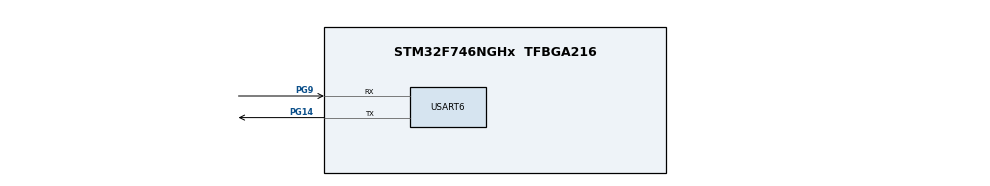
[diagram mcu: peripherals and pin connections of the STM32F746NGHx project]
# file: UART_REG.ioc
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Mcu.Family=STM32F7
Mcu.Name=STM32F746NGHx
Mcu.Package=TFBGA216
NVIC.PriorityGroup=NVIC_PRIORITYGROUP_4
NVIC.USART6_IRQn=true\:0\:0\:false\:false\:true\:true\:true\:true
PG14.Mode=Asynchronous
PG14.Signal=USART6_TX
PG9.Mode=Asynchronous
PG9.Signal=USART6_RX
ProjectManager.HeapSize=0x200
ProjectManager.StackSize=0x400
ProjectManager.TargetToolchain=STM32CubeIDE
RCC.HSE_VALUE=25000000
RCC.HSI_VALUE=16000000
RCC.LSE_VALUE=32768
RCC.USBFreq_Value=96000000
RCC.VCOOutputFreq_Value=192000000
USART6.VirtualMode-Asynchronous=VM_ASYNC
board=custom

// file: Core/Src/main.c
/* USER CODE BEGIN Header */
/**
  ******************************************************************************
  * @file           : main.c
  * @brief          : Main program body
  ******************************************************************************
  * @attention
  *
  * Copyright (c) 2023 STMicroelectronics.
  * All rights reserved.
  *
  * This software is licensed under terms that can be found in the LICENSE file
  * in the root directory of this software component.
  * If no LICENSE file comes with this software, it is provided AS-IS.
  *
  ******************************************************************************
  */
/* USER CODE END Header */
#include "main.h"

UART_HandleTypeDef huart6;

void SystemClock_Config(void);
static void MX_GPIO_Init(void);
static void MX_USART6_UART_Init(void);

/* USER CODE BEGIN 0 */

void uart_Send(uint8_t Txdata)
{
	/*********** STEPS FOLLOWED *************

		1. Write the data to send in the USART_DR register (this clears the TXE bit). Repeat this
			 for each data to be transmitted in case of single buffer.
		2. After writing the last data into the USART_DR register, wait until TC=1. This indicates
			 that the transmission of the last frame is complete. This is required for instance when
			 the USART is disabled or enters the Halt mode to avoid corrupting the last transmission.
    */
	 USART6->TDR = Txdata;
	 while(!(USART6->ISR & (1 << 6)));

}

void uart_Send_IT(void)
{

}

uint8_t uart_Receive(void)
{
	                      /*********** STEPS FOLLOWED *************/

	//1. Wait for the RXNE bit to set. It indicates that the data has been received and can be read.
    //2. Read the data from USART_DR  Register. This also clears the RXNE bit.

	while(!(USART6->ISR & (1 << 5)));
	uint8_t temp = USART6->RDR;

	return temp;
}

uint8_t uart_Receive_IT(void)
{

}

/* USER CODE END 0 */

int main(void)
{

  /* MCU Configuration--------------------------------------------------------*/

  /* Reset of all peripherals, Initializes the Flash interface and the Systick. */
  HAL_Init();

  /* Configure the system clock */
  SystemClock_Config();

  /* Initialize all configured peripherals */
  MX_GPIO_Init();
  MX_USART6_UART_Init();

  /* Infinite loop */
  while (1)
  {

  }
}

void SystemClock_Config(void)
{
  RCC_OscInitTypeDef RCC_OscInitStruct = {0};
  RCC_ClkInitTypeDef RCC_ClkInitStruct = {0};

  /** Configure the main internal regulator output voltage
  */
  __HAL_RCC_PWR_CLK_ENABLE();
  __HAL_PWR_VOLTAGESCALING_CONFIG(PWR_REGULATOR_VOLTAGE_SCALE3);

  /** Initializes the RCC Oscillators according to the specified parameters
  * in the RCC_OscInitTypeDef structure.
  */
  RCC_OscInitStruct.OscillatorType = RCC_OSCILLATORTYPE_HSI;
  RCC_OscInitStruct.HSIState = RCC_HSI_ON;
  RCC_OscInitStruct.HSICalibrationValue = RCC_HSICALIBRATION_DEFAULT;
  RCC_OscInitStruct.PLL.PLLState = RCC_PLL_NONE;
  if (HAL_RCC_OscConfig(&RCC_OscInitStruct) != HAL_OK)
  {
    Error_Handler();
  }

  /** Initializes the CPU, AHB and APB buses clocks
  */
  RCC_ClkInitStruct.ClockType = RCC_CLOCKTYPE_HCLK|RCC_CLOCKTYPE_SYSCLK
                              |RCC_CLOCKTYPE_PCLK1|RCC_CLOCKTYPE_PCLK2;
  RCC_ClkInitStruct.SYSCLKSource = RCC_SYSCLKSOURCE_HSI;
  RCC_ClkInitStruct.AHBCLKDivider = RCC_SYSCLK_DIV1;
  RCC_ClkInitStruct.APB1CLKDivider = RCC_HCLK_DIV1;
  RCC_ClkInitStruct.APB2CLKDivider = RCC_HCLK_DIV1;

  if (HAL_RCC_ClockConfig(&RCC_ClkInitStruct, FLASH_LATENCY_0) != HAL_OK)
  {
    Error_Handler();
  }
}

static void MX_USART6_UART_Init(void)
{

  huart6.Instance = USART6;
  huart6.Init.BaudRate = 115200;
  huart6.Init.WordLength = UART_WORDLENGTH_8B;
  huart6.Init.StopBits = UART_STOPBITS_1;
  huart6.Init.Parity = UART_PARITY_NONE;
  huart6.Init.Mode = UART_MODE_TX_RX;
  huart6.Init.HwFlowCtl = UART_HWCONTROL_NONE;
  huart6.Init.OverSampling = UART_OVERSAMPLING_16;
  huart6.Init.OneBitSampling = UART_ONE_BIT_SAMPLE_DISABLE;
  huart6.AdvancedInit.AdvFeatureInit = UART_ADVFEATURE_NO_INIT;
  if (HAL_UART_Init(&huart6) != HAL_OK)
  {
    Error_Handler();
  }

}

static void MX_GPIO_Init(void)
{

  /* GPIO Ports Clock Enable */
  __HAL_RCC_GPIOG_CLK_ENABLE();

}

void Error_Handler(void)
{
  __disable_irq();
  while (1)
  {
  }
}
